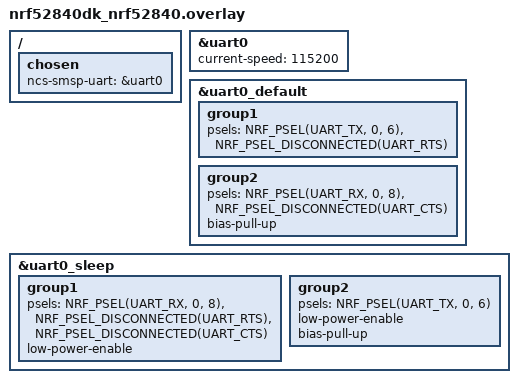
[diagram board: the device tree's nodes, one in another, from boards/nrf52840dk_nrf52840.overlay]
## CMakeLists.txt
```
cmake_minimum_required(VERSION 3.20.0)
find_package(Zephyr REQUIRED HINTS $ENV{ZEPHYR_BASE})
project(smsp_mcuboot_slave)

target_sources(app PRIVATE
	src/main.c
	src/smsp_slave.c
	src/mcuboot_rpc.c
)
```

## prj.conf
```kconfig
CONFIG_MAIN_STACK_SIZE=4096
CONFIG_SYSTEM_WORKQUEUE_STACK_SIZE=2048
CONFIG_HEAP_MEM_POOL_SIZE=16384

CONFIG_SERIAL=y
CONFIG_UART_INTERRUPT_DRIVEN=y
CONFIG_UART_LINE_CTRL=y

CONFIG_SHELL=n
CONFIG_LOG=n
CONFIG_CONSOLE=n

CONFIG_FLASH=y
CONFIG_FLASH_MAP=y
CONFIG_FLASH_PAGE_LAYOUT=y

CONFIG_BOOTLOADER_MCUBOOT=y
CONFIG_IMG_MANAGER=y
CONFIG_MCUBOOT_IMG_MANAGER=y
CONFIG_IMG_ENABLE_IMAGE_CHECK=y
CONFIG_STREAM_FLASH=y
CONFIG_STREAM_FLASH_ERASE=y
CONFIG_IMG_BLOCK_BUF_SIZE=512

CONFIG_ZCBOR=y
CONFIG_ZCBOR_CANONICAL=y

CONFIG_MCUMGR=n

CONFIG_REBOOT=y

CONFIG_DK_LIBRARY=y
```

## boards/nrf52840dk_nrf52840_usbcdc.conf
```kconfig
CONFIG_USB_DEVICE_STACK_NEXT=y
CONFIG_CDC_ACM_SERIAL_INITIALIZE_AT_BOOT=y
CONFIG_CDC_ACM_SERIAL_VID=0x1915
CONFIG_CDC_ACM_SERIAL_PID=0x5302
CONFIG_CDC_ACM_SERIAL_MANUFACTURER_STRING="Nordic Semiconductor ASA"
CONFIG_CDC_ACM_SERIAL_PRODUCT_STRING="SMSP MCUboot DK"
```

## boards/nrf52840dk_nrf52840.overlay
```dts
/ {
	chosen {
		ncs-smsp-uart = &uart0;
	};
};

&uart0 {
	status = "okay";
	current-speed = <115200>;
};

&uart0_default {
	group1 {
		psels = <NRF_PSEL(UART_TX, 0, 6)>,
			<NRF_PSEL_DISCONNECTED(UART_RTS)>;
	};
	group2 {
		psels = <NRF_PSEL(UART_RX, 0, 8)>,
			<NRF_PSEL_DISCONNECTED(UART_CTS)>;
		bias-pull-up;
	};
};

&uart0_sleep {
	group1 {
		psels = <NRF_PSEL(UART_RX, 0, 8)>,
			<NRF_PSEL_DISCONNECTED(UART_RTS)>,
			<NRF_PSEL_DISCONNECTED(UART_CTS)>;
		low-power-enable;
	};
	group2 {
		psels = <NRF_PSEL(UART_TX, 0, 6)>;
		low-power-enable;
		bias-pull-up;
	};
};
```

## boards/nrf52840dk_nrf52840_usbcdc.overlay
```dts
/ {
	chosen {
		ncs-smsp-uart = &cdc_acm_uart0;
	};
};

&zephyr_udc0 {
	cdc_acm_uart0: cdc_acm_uart0 {
		compatible = "zephyr,cdc-acm-uart";
	};
};
```

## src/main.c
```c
#include "mcuboot_rpc.h"
#include "smsp_slave.h"

#include <dk_buttons_and_leds.h>
#include <zephyr/device.h>
#include <zephyr/drivers/uart.h>
#include <zephyr/kernel.h>

static int dispatch(const uint8_t *req, size_t req_len, uint8_t *resp, size_t resp_cap, size_t *resp_len)
{
	return mcuboot_rpc_handle(req, req_len, resp, resp_cap, resp_len);
}

int main(void)
{
	const struct device *uart = DEVICE_DT_GET(DT_CHOSEN(ncs_smsp_uart));

	dk_leds_init();
	dk_set_led_on(DK_LED1);
	for (int i = 0; i < 500 && !device_is_ready(uart); i++) {
		k_msleep(10);
	}
	if (!device_is_ready(uart)) {
		dk_set_led_off(DK_LED1);
		return 0;
	}
	dk_set_led_off(DK_LED1);
	dk_set_led_on(DK_LED2);
	smsp_slave_run(uart, dispatch);
	return 0;
}
```

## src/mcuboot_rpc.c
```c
#include "mcuboot_rpc.h"

#include <ctype.h>
#include <errno.h>
#include <string.h>
#include <zephyr/dfu/flash_img.h>
#include <zephyr/dfu/mcuboot.h>
#include <zephyr/storage/flash_map.h>
#include <zcbor_decode.h>
#include <zcbor_encode.h>

#define RPC_HDR_MAX 512
#define SHA256_HEX_LEN 64
#define IMAGE_MAGIC 0x96f3b83d
#define IMAGE_TLV_INFO_MAGIC 0x6907
#define IMAGE_TLV_PROT_INFO_MAGIC 0x6908
#define IMAGE_TLV_SHA256 0x10
#define IMAGE_HASH_LEN 32

struct image_header {
	uint32_t ih_magic;
	uint32_t ih_load_addr;
	uint16_t ih_hdr_size;
	uint16_t ih_protect_tlv_size;
	uint32_t ih_img_size;
	uint32_t ih_flags;
	uint8_t ih_ver_major;
	uint8_t ih_ver_minor;
	uint16_t ih_ver_revision;
	uint32_t ih_ver_build_num;
	uint32_t ih_pad1;
} __packed;

struct image_tlv_info {
	uint16_t it_magic;
	uint16_t it_tlv_tot;
} __packed;

struct image_tlv {
	uint16_t it_type;
	uint16_t it_len;
} __packed;

struct upload_ctx {
	struct flash_img_context flash;
	bool active;
	uint32_t slot;
	char sha256[SHA256_HEX_LEN + 1];
};

static struct upload_ctx upload;

static int hex_nibble(char c)
{
	if (c >= '0' && c <= '9') {
		return c - '0';
	}
	if (c >= 'a' && c <= 'f') {
		return c - 'a' + 10;
	}
	if (c >= 'A' && c <= 'F') {
		return c - 'A' + 10;
	}
	return -1;
}

static int hex_to_bin(const char *hex, uint8_t *out, size_t out_len)
{
	if (strlen(hex) != out_len * 2) {
		return -1;
	}
	for (size_t i = 0; i < out_len; i++) {
		int hi = hex_nibble(hex[i * 2]);
		int lo = hex_nibble(hex[i * 2 + 1]);

		if (hi < 0 || lo < 0) {
			return -1;
		}
		out[i] = (uint8_t)((hi << 4) | lo);
	}
	return 0;
}

static void bin_to_hex_lower(const uint8_t *bin, size_t bin_len, char *hex, size_t hex_cap)
{
	static const char digits[] = "0123456789abcdef";

	if (hex_cap < bin_len * 2 + 1) {
		hex[0] = '\0';
		return;
	}
	for (size_t i = 0; i < bin_len; i++) {
		hex[i * 2] = digits[bin[i] >> 4];
		hex[i * 2 + 1] = digits[bin[i] & 0x0f];
	}
	hex[bin_len * 2] = '\0';
}

static int flash_area_read_id(uint8_t area_id, off_t off, void *dst, size_t len)
{
	const struct flash_area *fa;
	int rc;

	rc = flash_area_open(area_id, &fa);
	if (rc != 0) {
		return rc;
	}
	rc = flash_area_read(fa, off, dst, len);
	flash_area_close(fa);
	return rc;
}

static int find_image_tlv_area(uint8_t area_id, size_t *start_off, size_t *end_off, uint16_t magic)
{
	struct image_tlv_info tlv_info;
	int rc;

	rc = flash_area_read_id(area_id, *start_off, &tlv_info, sizeof(tlv_info));
	if (rc != 0) {
		return rc;
	}
	if (tlv_info.it_magic != magic) {
		return -ENOENT;
	}
	*start_off += sizeof(tlv_info);
	*end_off = *start_off + tlv_info.it_tlv_tot;
	return 0;
}

static int read_image_sha256(uint8_t area_id, uint8_t hash[IMAGE_HASH_LEN])
{
	struct image_header hdr;
	struct image_tlv tlv;
	size_t data_off;
	size_t data_end;
	bool hash_found;
	int rc;

	rc = flash_area_read_id(area_id, boot_get_image_start_offset(area_id), &hdr, sizeof(hdr));
	if (rc != 0) {
		return rc;
	}
	if (hdr.ih_magic != IMAGE_MAGIC) {
		return -EINVAL;
	}
	data_off = boot_get_image_start_offset(area_id) + hdr.ih_hdr_size + hdr.ih_img_size;
	rc = find_image_tlv_area(area_id, &data_off, &data_end, IMAGE_TLV_PROT_INFO_MAGIC);
	if (rc == 0) {
		data_off = data_end - sizeof(struct image_tlv_info);
	}
	rc = find_image_tlv_area(area_id, &data_off, &data_end, IMAGE_TLV_INFO_MAGIC);
	if (rc != 0) {
		return rc;
	}
	hash_found = false;
	while (data_off + sizeof(tlv) <= data_end) {
		rc = flash_area_read_id(area_id, data_off, &tlv, sizeof(tlv));
		if (rc != 0) {
			return rc;
		}
		if (tlv.it_type == 0xff && tlv.it_len == 0xffff) {
			return -EINVAL;
		}
		if (tlv.it_type != IMAGE_TLV_SHA256 || tlv.it_len != IMAGE_HASH_LEN) {
			data_off += sizeof(tlv) + tlv.it_len;
			continue;
		}
		if (hash_found) {
			return -EINVAL;
		}
		hash_found = true;
		data_off += sizeof(tlv);
		return flash_area_read_id(area_id, data_off, hash, IMAGE_HASH_LEN);
	}
	return hash_found ? 0 : -ENOENT;
}

static int encode_frame(const uint8_t *hdr, size_t hdr_len, const uint8_t *data, size_t data_len,
			uint8_t *out, size_t out_cap, size_t *out_len)
{
	if (hdr_len > UINT16_MAX || out_cap < 2 + hdr_len + data_len) {
		return -1;
	}
	out[0] = (uint8_t)(hdr_len >> 8);
	out[1] = (uint8_t)(hdr_len & 0xff);
	memcpy(out + 2, hdr, hdr_len);
	if (data_len > 0) {
		memcpy(out + 2 + hdr_len, data, data_len);
	}
	*out_len = 2 + hdr_len + data_len;
	return 0;
}

static int encode_error(const char *for_type, int code, const char *msg, uint8_t *out, size_t out_cap,
			size_t *out_len)
{
	uint8_t hdr[RPC_HDR_MAX];
	zcbor_state_t state[4];
	size_t hdr_len;

	zcbor_new_encode_state(state, ARRAY_SIZE(state), hdr, sizeof(hdr), 0);
	if (!zcbor_map_start_encode(state, 4) || !zcbor_tstr_put_lit(state, "type") ||
	    !zcbor_tstr_put_lit(state, "error") || !zcbor_tstr_put_lit(state, "for")) {
		return -1;
	}
	if (for_type) {
		if (!zcbor_tstr_encode_ptr(state, for_type, strlen(for_type))) {
			return -1;
		}
	} else if (!zcbor_tstr_put_lit(state, "")) {
		return -1;
	}
	if (!zcbor_tstr_put_lit(state, "code") || !zcbor_int32_put(state, code) ||
	    !zcbor_tstr_put_lit(state, "message") ||
	    !zcbor_tstr_encode_ptr(state, msg, strlen(msg)) ||
	    !zcbor_map_end_encode(state, 4)) {
		return -1;
	}
	hdr_len = (size_t)(state[0].payload - hdr);
	return encode_frame(hdr, hdr_len, NULL, 0, out, out_cap, out_len);
}

static bool map_key_match(struct zcbor_string *key, const char *lit)
{
	size_t len = strlen(lit);

	return key->len == len && memcmp(key->value, lit, len) == 0;
}

static int decode_upload_fields(const uint8_t *hdr, size_t hdr_len, uint32_t *slot, char *sha, size_t sha_cap,
				uint64_t *total, uint64_t *offset, uint64_t *length)
{
	zcbor_state_t state[4];
	struct zcbor_string key;
	bool found_type;

	zcbor_new_decode_state(state, ARRAY_SIZE(state), (uint8_t *)hdr, hdr_len, 0, NULL, 0);
	if (!zcbor_map_start_decode(state)) {
		return -1;
	}
	found_type = false;
	for (;;) {
		if (zcbor_map_end_decode(state)) {
			break;
		}
		if (!zcbor_tstr_decode(state, &key)) {
			return -1;
		}
		if (map_key_match(&key, "type")) {
			struct zcbor_string type_val;

			if (!zcbor_tstr_decode(state, &type_val) || type_val.len != 12 ||
			    memcmp(type_val.value, "upload_image", 12) != 0) {
				return -1;
			}
			found_type = true;
		} else if (map_key_match(&key, "slot")) {
			int32_t v;

			if (!zcbor_int32_decode(state, &v)) {
				return -1;
			}
			*slot = (uint32_t)v;
		} else if (map_key_match(&key, "sha256")) {
			struct zcbor_string s;

			if (!zcbor_tstr_decode(state, &s) || s.len >= sha_cap) {
				return -1;
			}
			memcpy(sha, s.value, s.len);
			sha[s.len] = '\0';
		} else if (map_key_match(&key, "total")) {
			uint64_t v;

			if (!zcbor_uint64_decode(state, &v)) {
				return -1;
			}
			*total = v;
		} else if (map_key_match(&key, "offset")) {
			uint64_t v;

			if (!zcbor_uint64_decode(state, &v)) {
				return -1;
			}
			*offset = v;
		} else if (map_key_match(&key, "length")) {
			uint64_t v;

			if (!zcbor_uint64_decode(state, &v)) {
				return -1;
			}
			*length = v;
		} else if (!zcbor_any_skip(state, NULL)) {
			return -1;
		}
	}
	return found_type ? 0 : -1;
}

static int decode_type_list_images(const uint8_t *hdr, size_t hdr_len)
{
	static const char lit[] = "list_images";

	if (hdr_len < sizeof(lit) - 1) {
		return -1;
	}
	for (size_t i = 0; i + sizeof(lit) - 1 <= hdr_len; i++) {
		if (memcmp(hdr + i, lit, sizeof(lit) - 1) == 0) {
			return 0;
		}
	}
	return -1;
}

static uint8_t slot_to_area_id(uint32_t slot)
{
	return slot == 0 ? PARTITION_ID(slot1_partition) : PARTITION_ID(slot0_partition);
}

static int slot_image_count(void)
{
	struct mcuboot_img_header hdr;
	int count = 0;

	if (boot_read_bank_header(PARTITION_ID(slot0_partition), &hdr, sizeof(hdr)) == 0) {
		count++;
	}
	if (boot_read_bank_header(PARTITION_ID(slot1_partition), &hdr, sizeof(hdr)) == 0) {
		count++;
	}
	return count;
}

static int append_image(zcbor_state_t *state, uint8_t area_id, uint32_t slot_idx)
{
	struct mcuboot_img_header hdr;
	uint8_t hash_bin[IMAGE_HASH_LEN];
	char hash_hex[SHA256_HEX_LEN + 1];
	int err = boot_read_bank_header(area_id, &hdr, sizeof(hdr));
	bool active = boot_fetch_active_slot() == area_id;

	if (err != 0) {
		return 0;
	}
	hash_hex[0] = '\0';
	if (read_image_sha256(area_id, hash_bin) == 0) {
		bin_to_hex_lower(hash_bin, sizeof(hash_bin), hash_hex, sizeof(hash_hex));
	}
	if (!zcbor_map_start_encode(state, 4) || !zcbor_tstr_put_lit(state, "slot") ||
	    !zcbor_int32_put(state, (int32_t)slot_idx) || !zcbor_tstr_put_lit(state, "version") ||
	    !zcbor_int32_put(state, (int32_t)hdr.h.v1.sem_ver.build_num) ||
	    !zcbor_tstr_put_lit(state, "hash") ||
	    !zcbor_tstr_encode_ptr(state, hash_hex, strlen(hash_hex)) ||
	    !zcbor_tstr_put_lit(state, "active") || !zcbor_bool_put(state, active) ||
	    !zcbor_map_end_encode(state, 4)) {
		return -1;
	}
	return 1;
}

static int handle_list_images(uint8_t *out, size_t out_cap, size_t *out_len)
{
	uint8_t hdr[RPC_HDR_MAX];
	zcbor_state_t state[8];
	size_t hdr_len;
	int image_count = slot_image_count();

	zcbor_new_encode_state(state, ARRAY_SIZE(state), hdr, sizeof(hdr), 0);
	if (!zcbor_map_start_encode(state, 2) || !zcbor_tstr_put_lit(state, "type") ||
	    !zcbor_tstr_put_lit(state, "list_images") || !zcbor_tstr_put_lit(state, "images") ||
	    !zcbor_list_start_encode(state, image_count)) {
		return -1;
	}
	if (append_image(state, PARTITION_ID(slot0_partition), 0) < 0 ||
	    append_image(state, PARTITION_ID(slot1_partition), 1) < 0) {
		return -1;
	}
	if (!zcbor_list_end_encode(state, image_count) || !zcbor_map_end_encode(state, 2)) {
		return -1;
	}
	hdr_len = (size_t)(state[0].payload - hdr);
	return encode_frame(hdr, hdr_len, NULL, 0, out, out_cap, out_len);
}

static int finalize_upload(uint8_t area_id)
{
	uint8_t hash_bin[32];
	struct flash_img_check fic = {0};

	if (flash_img_buffered_write(&upload.flash, NULL, 0, true) != 0) {
		return -1;
	}
	if (hex_to_bin(upload.sha256, hash_bin, sizeof(hash_bin)) != 0) {
		return -1;
	}
	fic.match = hash_bin;
	fic.clen = sizeof(hash_bin);
	return flash_img_check(&upload.flash, &fic, area_id);
}

static int handle_upload_image(const uint8_t *rpc_hdr, size_t rpc_hdr_len, const uint8_t *data, size_t data_len,
			       uint8_t *out, size_t out_cap, size_t *out_len)
{
	uint32_t slot = 0;
	char sha[SHA256_HEX_LEN + 1];
	uint64_t total = 0;
	uint64_t offset = 0;
	uint64_t length = 0;
	uint8_t area_id;
	size_t written;
	uint8_t hdr[RPC_HDR_MAX];
	zcbor_state_t state[4];
	uint64_t remaining;
	size_t hdr_len;

	if (decode_upload_fields(rpc_hdr, rpc_hdr_len, &slot, sha, sizeof(sha), &total, &offset, &length) != 0) {
		return encode_error("upload_image", 2, "invalid header", out, out_cap, out_len);
	}
	if (length != data_len) {
		return encode_error("upload_image", 4, "length mismatch", out, out_cap, out_len);
	}
	area_id = slot_to_area_id(slot);
	if (offset == 0) {
		if (flash_img_init_id(&upload.flash, area_id) != 0) {
			return encode_error("upload_image", 2, "flash init failed", out, out_cap, out_len);
		}
		upload.active = true;
		upload.slot = slot;
		strncpy(upload.sha256, sha, sizeof(upload.sha256) - 1);
	} else if (!upload.active || upload.slot != slot || strncmp(upload.sha256, sha, sizeof(upload.sha256)) != 0) {
		return encode_error("upload_image", 3, "offset mismatch", out, out_cap, out_len);
	}
	written = flash_img_bytes_written(&upload.flash);
	if (offset != written) {
		return encode_error("upload_image", 3, "offset mismatch", out, out_cap, out_len);
	}
	if (data_len > 0 && flash_img_buffered_write(&upload.flash, data, data_len, false) != 0) {
		return encode_error("upload_image", 2, "flash write failed", out, out_cap, out_len);
	}
	written = flash_img_bytes_written(&upload.flash);
	remaining = total > written ? total - written : 0;
	if (remaining == 0 && total > 0) {
		if (finalize_upload(area_id) != 0) {
			return encode_error("upload_image", 2, "hash mismatch", out, out_cap, out_len);
		}
		upload.active = false;
	}
	zcbor_new_encode_state(state, ARRAY_SIZE(state), hdr, sizeof(hdr), 0);
	if (!zcbor_map_start_encode(state, 3) || !zcbor_tstr_put_lit(state, "type") ||
	    !zcbor_tstr_put_lit(state, "upload_image") || !zcbor_tstr_put_lit(state, "offset") ||
	    !zcbor_uint64_put(state, written) || !zcbor_tstr_put_lit(state, "remaining") ||
	    !zcbor_uint64_put(state, remaining) || !zcbor_map_end_encode(state, 3)) {
		return -1;
	}
	hdr_len = (size_t)(state[0].payload - hdr);
	return encode_frame(hdr, hdr_len, NULL, 0, out, out_cap, out_len);
}

int mcuboot_rpc_handle(const uint8_t *frame, size_t frame_len, uint8_t *out, size_t out_cap, size_t *out_len)
{
	uint16_t hdr_len;
	const uint8_t *rpc_hdr;
	const uint8_t *data;
	size_t data_len;

	if (frame_len < 2) {
		return encode_error(NULL, 2, "invalid frame", out, out_cap, out_len);
	}
	hdr_len = ((uint16_t)frame[0] << 8) | frame[1];
	if ((size_t)2 + hdr_len > frame_len || hdr_len > RPC_HDR_MAX) {
		return encode_error(NULL, 2, "invalid frame", out, out_cap, out_len);
	}
	rpc_hdr = frame + 2;
	data = frame + 2 + hdr_len;
	data_len = frame_len - 2 - hdr_len;
	if (decode_type_list_images(rpc_hdr, hdr_len) == 0) {
		return handle_list_images(out, out_cap, out_len);
	}
	{
		uint32_t slot = 0;
		char sha[SHA256_HEX_LEN + 1];
		uint64_t total = 0;
		uint64_t offset = 0;
		uint64_t length = 0;

		if (decode_upload_fields(rpc_hdr, hdr_len, &slot, sha, sizeof(sha), &total, &offset, &length) == 0) {
			return handle_upload_image(rpc_hdr, hdr_len, data, data_len, out, out_cap, out_len);
		}
	}
	return encode_error(NULL, 1, "unknown type", out, out_cap, out_len);
}
```

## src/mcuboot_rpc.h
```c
#ifndef MCUBOOT_RPC_H_
#define MCUBOOT_RPC_H_

#include <stddef.h>
#include <stdint.h>

int mcuboot_rpc_handle(const uint8_t *frame, size_t frame_len, uint8_t *out, size_t out_cap,
		       size_t *out_len);

#endif
```

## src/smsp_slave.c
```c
#include "smsp_slave.h"

#include <dk_buttons_and_leds.h>
#include <string.h>
#include <zephyr/device.h>
#include <zephyr/drivers/uart.h>
#include <zephyr/kernel.h>

#define SMSP_INIT_PREFIX "parameters?"
#define SMSP_PARAMS "1,1,20000,1,256\n"

enum smsp_status {
	SMSP_LAST = 0,
	SMSP_MORE = 1,
	SMSP_CANCEL = 2,
};

#define UART_RX_Q 512
static uint8_t rx_q[UART_RX_Q];
static volatile uint16_t rx_w;
static volatile uint16_t rx_r;

static void uart_rx_isr(const struct device *dev, void *user_data)
{
	ARG_UNUSED(user_data);

	while (uart_irq_update(dev) && uart_irq_rx_ready(dev)) {
		uint8_t c;
		uint16_t next;

		if (uart_fifo_read(dev, &c, 1) != 1) {
			break;
		}
		next = (uint16_t)((rx_w + 1U) % UART_RX_Q);
		if (next == rx_r) {
			continue;
		}
		rx_q[rx_w] = c;
		rx_w = next;
	}
}

static void uart_rx_start(const struct device *uart)
{
	rx_w = 0;
	rx_r = 0;
	uart_irq_callback_set(uart, uart_rx_isr);
	uart_irq_rx_enable(uart);
}

static int uart_read_byte(const struct device *uart, uint8_t *byte, int32_t timeout_ms)
{
	ARG_UNUSED(uart);
	for (int32_t i = 0; i < timeout_ms; i++) {
		if (rx_r != rx_w) {
			*byte = rx_q[rx_r];
			rx_r = (uint16_t)((rx_r + 1U) % UART_RX_Q);
			return 0;
		}
		k_msleep(1);
	}
	return -1;
}

static int uart_write_all(const struct device *uart, const uint8_t *data, size_t len)
{
	uart_irq_rx_disable(uart);
	for (size_t i = 0; i < len; i++) {
		uart_poll_out(uart, data[i]);
	}
	uart_err_check(uart);
	uart_irq_rx_enable(uart);
	return 0;
}

static int read_exact(const struct device *uart, uint8_t *buf, size_t len)
{
	for (size_t i = 0; i < len; i++) {
		if (uart_read_byte(uart, &buf[i], 5000) != 0) {
			return -1;
		}
	}
	return 0;
}

static int parse_header(const uint8_t *hdr, enum smsp_status *st, uint8_t *seq, uint16_t *plen)
{
	*st = hdr[0] & 0x03;
	*seq = (hdr[0] >> 4) & 0x0f;
	if ((hdr[0] & 0x04) == 0) {
		return -1;
	}
	*plen = ((uint16_t)hdr[1] << 8) | hdr[2];
	return 0;
}

static int send_header(const struct device *uart, enum smsp_status st, uint8_t seq, const uint8_t *payload,
		       size_t payload_len)
{
	uint8_t hdr[3];
	hdr[0] = (uint8_t)st | 0x04 | (seq << 4);
	hdr[1] = (uint8_t)(payload_len >> 8);
	hdr[2] = (uint8_t)(payload_len & 0xff);
	uart_write_all(uart, hdr, sizeof(hdr));
	if (payload_len > 0) {
		uart_write_all(uart, payload, payload_len);
	}
	return 0;
}

static int send_ack(const struct device *uart)
{
	return send_header(uart, SMSP_LAST, 0, NULL, 0);
}

static int read_message(const struct device *uart, uint8_t *buf, size_t cap, size_t *out_len, bool *is_last)
{
	uint8_t hdr[3];
	enum smsp_status st;
	uint8_t seq;
	uint16_t plen;
	size_t total = 0;
	uint8_t expect = 0;

	*out_len = 0;
	for (;;) {
		if (read_exact(uart, hdr, sizeof(hdr)) != 0) {
			return -1;
		}
		if (parse_header(hdr, &st, &seq, &plen) != 0) {
			return -1;
		}
		if (seq != expect) {
			return -1;
		}
		expect = (expect + 1) & 0x0f;
		if (total + plen > cap) {
			return -1;
		}
		if (plen > 0 && read_exact(uart, buf + total, plen) != 0) {
			return -1;
		}
		total += plen;
		if (st == SMSP_CANCEL) {
			return -1;
		}
		if (st == SMSP_LAST) {
			*is_last = true;
			*out_len = total;
			return 0;
		}
		send_ack(uart);
	}
}

static int send_fragments(const struct device *uart, const uint8_t *data, size_t len)
{
	size_t off = 0;
	uint8_t seq = 0;

	while (off < len) {
		size_t chunk = len - off;
		if (chunk > SMSP_FRAG_MAX) {
			chunk = SMSP_FRAG_MAX;
		}
		bool last = (off + chunk) >= len;
		enum smsp_status st = last ? SMSP_LAST : SMSP_MORE;
		if (send_header(uart, st, seq, data + off, chunk) != 0) {
			return -1;
		}
		off += chunk;
		seq = (seq + 1) & 0x0f;
		if (!last) {
			uint8_t ack_hdr[3];
			if (read_exact(uart, ack_hdr, sizeof(ack_hdr)) != 0) {
				return -1;
			}
			enum smsp_status ast;
			uint8_t aseq;
			uint16_t alen;
			if (parse_header(ack_hdr, &ast, &aseq, &alen) != 0 || ast != SMSP_LAST || alen != 0) {
				return -1;
			}
		}
	}
	return 0;
}

static int wait_init(const struct device *uart)
{
	const size_t plen = sizeof(SMSP_INIT_PREFIX) - 1;

	for (;;) {
		size_t i = 0;

		while (i < plen) {
			uint8_t b;

			if (uart_read_byte(uart, &b, 60000) != 0) {
				return -1;
			}
			if (b != (uint8_t)SMSP_INIT_PREFIX[i]) {
				i = (b == (uint8_t)SMSP_INIT_PREFIX[0]) ? 1 : 0;
				continue;
			}
			i++;
		}
		{
			uint8_t b;

			if (uart_read_byte(uart, &b, 200) != 0 || b == 0) {
				break;
			}
			if (b == (uint8_t)SMSP_INIT_PREFIX[0]) {
				continue;
			}
		}
	}
	if (uart_write_all(uart, (const uint8_t *)SMSP_PARAMS, strlen(SMSP_PARAMS)) != 0) {
		return -1;
	}
	dk_set_led_on(DK_LED4);
	k_msleep(50);
	return 0;
}

int smsp_slave_run(const struct device *uart, smsp_request_fn handler)
{
	static uint8_t req[SMSP_RX_MAX];
	static uint8_t resp[SMSP_TX_MAX];
	size_t req_len;
	size_t resp_len;
	bool is_last;

	if (!device_is_ready(uart)) {
		return -1;
	}
	uart_rx_start(uart);
	for (;;) {
		if (wait_init(uart) != 0) {
			continue;
		}
		if (read_message(uart, req, sizeof(req), &req_len, &is_last) != 0) {
			continue;
		}
		resp_len = 0;
		if (handler(req, req_len, resp, sizeof(resp), &resp_len) != 0) {
			continue;
		}
		if (send_fragments(uart, resp, resp_len) != 0) {
			continue;
		}
	}
}
```

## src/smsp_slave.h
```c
#ifndef SMSP_SLAVE_H_
#define SMSP_SLAVE_H_

#include <stddef.h>
#include <stdint.h>
#include <zephyr/device.h>

#define SMSP_FRAG_MAX 256
#define SMSP_RX_MAX 8192
#define SMSP_TX_MAX 8192

typedef int (*smsp_request_fn)(const uint8_t *req, size_t req_len, uint8_t *resp,
			       size_t resp_cap, size_t *resp_len);

int smsp_slave_run(const struct device *uart, smsp_request_fn handler);

#endif
```
